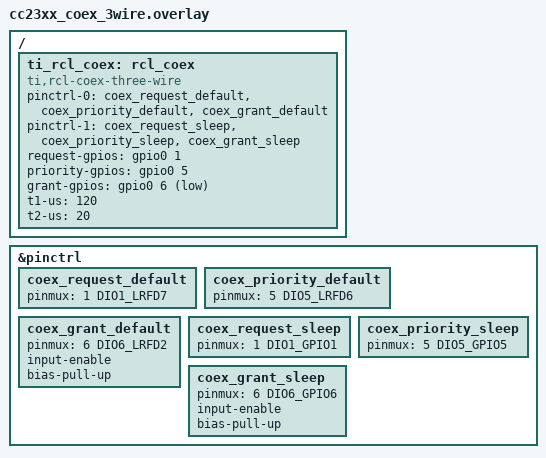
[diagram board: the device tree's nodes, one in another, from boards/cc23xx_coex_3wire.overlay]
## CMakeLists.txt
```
# SPDX-License-Identifier: Apache-2.0

cmake_minimum_required(VERSION 3.28.0)
find_package(Zephyr REQUIRED HINTS $ENV{ZEPHYR_BASE})
project(peripheral)

target_sources(app PRIVATE
  src/main.c
)
```

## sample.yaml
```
sample:
  name: Bluetooth Peripheral
  description: Demonstrates the Bluetooth LE Peripheral role
tests:
  sample.bluetooth.peripheral:
    harness: bluetooth
    platform_allow:
      - qemu_x86
      - lp_em_cc2340r5
      - lp_em_cc2340r5moda
      - lp_em_cc2340r53
      - lp_em_cc2340r53_wcsp
      - lp_em_cc2745r10_q1/cc2745r10_q1
      - lp_em_cc2745r10_q1/cc2755r10
      - lp_em_cc2755p10
      - lp_em_cc2755p20
      - nucleo_wb55rg
      - lp_em_cc35x1/cc3551e
    integration_platforms:
      - qemu_x86
    tags: bluetooth
  sample.bluetooth.peripheral.ti_lpf3.coex_3wire_cc23xx:
    harness: bluetooth
    platform_allow:
      - lp_em_cc2340r5
      - lp_em_cc2340r5moda
      - lp_em_cc2340r53
      - lp_em_cc2340r53_wcsp
    extra_args: EXTRA_DTC_OVERLAY_FILE=boards/cc23xx_coex_3wire.overlay
    extra_configs:
      - CONFIG_RCL_COEX=y
    tags: bluetooth
  sample.bluetooth.peripheral.ti_lpf3.coex_3wire_cc27xx:
    harness: bluetooth
    platform_allow:
      - lp_em_cc2745r10_q1/cc2745r10_q1
      - lp_em_cc2745r10_q1/cc2755r10
      - lp_em_cc2755p10
      - lp_em_cc2755p20
    extra_args: EXTRA_DTC_OVERLAY_FILE=boards/cc27xx_coex_3wire.overlay
    extra_configs:
      - CONFIG_RCL_COEX=y
    tags: bluetooth
  sample.bluetooth.peripheral.x_nucleo_idb05a1_shield:
    harness: bluetooth
    platform_allow: nucleo_l4r5zi
    depends_on:
      - arduino_spi
      - arduino_gpio
    extra_args: SHIELD=x_nucleo_idb05a1
    integration_platforms:
      - nucleo_l4r5zi
  sample.bluetooth.peripheral.no_blobs:
    extra_args:
      - CONFIG_BUILD_ONLY_NO_BLOBS=y
    platform_allow:
      - esp32_devkitc/esp32/procpu
      - esp32s3_devkitc/esp32s3/procpu
      - esp8684_devkitm
      - esp32c3_devkitc
      - esp32c6_devkitc/esp32c6/hpcore
      - esp32h2_devkitm
      - sltb010a/efr32bg22c224f512im40
      - xg24_rb4187c/efr32mg24b220f1536im48
      - xg27_dk2602a/efr32bg27c140f768im40
      - xg29_rb4412a/efr32mg29b140f1024im40
      - frdm_mcxw71
      - frdm_mcxw72
      - frdm_rw612
    build_only: true
```

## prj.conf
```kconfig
# Increased stack due to settings API usage
CONFIG_SYSTEM_WORKQUEUE_STACK_SIZE=2048

CONFIG_BT=y
CONFIG_LOG=y
CONFIG_BT_SMP=y
CONFIG_BT_PERIPHERAL=y
CONFIG_BT_DIS=y
CONFIG_BT_ATT_PREPARE_COUNT=5
CONFIG_BT_BAS=y
CONFIG_BT_HRS=y
CONFIG_BT_IAS=y
CONFIG_BT_CTS=y
CONFIG_BT_CTS_HELPER_API=y
CONFIG_BT_PRIVACY=y
CONFIG_BT_DEVICE_NAME="Zephyr Peripheral Sample Long Name"
CONFIG_BT_DEVICE_APPEARANCE=833
CONFIG_BT_DEVICE_NAME_DYNAMIC=y
CONFIG_BT_DEVICE_NAME_MAX=65

CONFIG_BT_KEYS_OVERWRITE_OLDEST=y
CONFIG_BT_SETTINGS=y
CONFIG_FLASH=y
CONFIG_FLASH_MAP=y
CONFIG_NVS=y
CONFIG_SETTINGS=y
```

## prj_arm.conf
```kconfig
CONFIG_BLUETOOTH=y
CONFIG_BLUETOOTH_LE=y
CONFIG_BLUETOOTH_DEBUG=y
CONFIG_BLUETOOTH_SMP=y
CONFIG_BLUETOOTH_SIGNING=y
CONFIG_TINYCRYPT=y
CONFIG_TINYCRYPT_AES=y
CONFIG_TEST_RANDOM_GENERATOR=y
CONFIG_BLUETOOTH_PERIPHERAL=y
```

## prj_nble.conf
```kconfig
CONFIG_BLUETOOTH=y
CONFIG_BLUETOOTH_CUSTOM=y
CONFIG_NBLE=y
CONFIG_BLUETOOTH_DEBUG_LOG=y
CONFIG_BLUETOOTH_ATT_PREPARE_COUNT=2
CONFIG_BLUETOOTH_DEVICE_NAME="Test peripheral"
```

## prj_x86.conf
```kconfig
CONFIG_TEST_RANDOM_GENERATOR=y
CONFIG_BLUETOOTH=y
CONFIG_BLUETOOTH_LE=y
CONFIG_BLUETOOTH_DEBUG=y
CONFIG_BLUETOOTH_SMP=y
CONFIG_BLUETOOTH_SIGNING=y
CONFIG_TINYCRYPT=y
CONFIG_TINYCRYPT_AES=y
CONFIG_BLUETOOTH_PERIPHERAL=y
CONFIG_BLUETOOTH_GATT_DYNAMIC_DB=y
```

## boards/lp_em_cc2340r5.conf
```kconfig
# Disable persistent storage to reduce RAM on cc2340r5
CONFIG_BT_KEYS_OVERWRITE_OLDEST=n
CONFIG_BT_SETTINGS=n
CONFIG_FLASH=n
CONFIG_FLASH_MAP=n
CONFIG_NVS=n
CONFIG_SETTINGS=n

# ATT prepare write not needed without persistent storage; 2 bufs sufficient for basic writes
CONFIG_BT_ATT_PREPARE_COUNT=2

# GATT cache is volatile without BT_SETTINGS (lost on reset), so caching provides no benefit
CONFIG_BT_GATT_CACHING=n
```

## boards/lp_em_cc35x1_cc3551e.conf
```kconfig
CONFIG_BT_HCI_TI_CC35XX=y

CONFIG_WIFI_TI_CC35XX=y
CONFIG_NET_L2_ETHERNET=y
CONFIG_NETWORKING=y
CONFIG_WIFI=y

# The CC35xx HSM/PSA integration is not ready for the Zephyr Bluetooth host.
CONFIG_ENTROPY_CC35XX_RNG=n
CONFIG_CRYPTO_TI_CC35XX=n
CONFIG_BT_GATT_CACHING=n
CONFIG_BT_SMP=n
CONFIG_BT_PRIVACY=n
CONFIG_BT_KEYS_OVERWRITE_OLDEST=n

CONFIG_BT_PHY_UPDATE=n
CONFIG_BT_AUTO_PHY_UPDATE=n

# Below memory constraints are enforced by the Wi-Fi stack
CONFIG_HEAP_MEM_POOL_SIZE=81920
CONFIG_MAIN_STACK_SIZE=61440
CONFIG_NET_TX_STACK_SIZE=2048
CONFIG_NET_RX_STACK_SIZE=2048
CONFIG_DYNAMIC_THREAD_PREFER_POOL=y
CONFIG_DYNAMIC_THREAD_POOL_SIZE=3
CONFIG_DYNAMIC_THREAD_STACK_SIZE=8192
CONFIG_NET_PKT_RX_COUNT=10
CONFIG_NET_PKT_TX_COUNT=10
CONFIG_NET_BUF_RX_COUNT=20
CONFIG_NET_BUF_TX_COUNT=20
CONFIG_NET_MAX_CONTEXTS=10
```

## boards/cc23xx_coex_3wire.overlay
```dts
/*
 * Copyright (c) 2026 Texas Instruments Incorporated
 *
 * SPDX-License-Identifier: Apache-2.0
 */

#include <zephyr/dt-bindings/pinctrl/cc23x0-pinctrl.h>
#include <zephyr/dt-bindings/gpio/gpio.h>

&pinctrl {
	coex_request_default: coex_request_default {
		pinmux = <1 DIO1_LRFD7>;	/* REQUEST - output using LRFD7 */
	};

	coex_priority_default: coex_priority_default {
		pinmux = <5 DIO5_LRFD6>;	/* PRIORITY - output using LRFD6 */
	};

	coex_grant_default: coex_grant_default {
		pinmux = <6 DIO6_LRFD2>;	/* GRANT - input using LRFD2 */
		input-enable;
		bias-pull-up;
	};

	coex_request_sleep: coex_request_sleep {
		pinmux = <1 DIO1_GPIO1>;
	};

	coex_priority_sleep: coex_priority_sleep {
		pinmux = <5 DIO5_GPIO5>;
	};

	coex_grant_sleep: coex_grant_sleep {
		pinmux = <6 DIO6_GPIO6>;
		input-enable;
		bias-pull-up;
	};
};

/ {
	ti_rcl_coex: rcl_coex {
		compatible = "ti,rcl-coex-three-wire";
		status = "okay";

		pinctrl-0 = <&coex_request_default &coex_priority_default &coex_grant_default>;
		pinctrl-1 = <&coex_request_sleep &coex_priority_sleep &coex_grant_sleep>;
		pinctrl-names = "default", "sleep";

		request-gpios = <&gpio0 1 GPIO_ACTIVE_HIGH>;
		priority-gpios = <&gpio0 5 GPIO_ACTIVE_HIGH>;
		grant-gpios = <&gpio0 6 GPIO_ACTIVE_LOW>;

		t1-us = <120>;  /* Time between REQUEST and RF activity (90-150 µs) */
		t2-us = <20>;   /* Priority indication time (15-20 µs) */
	};
};
```

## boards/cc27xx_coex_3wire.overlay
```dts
/*
 * Copyright (c) 2026 Texas Instruments Incorporated
 *
 * SPDX-License-Identifier: Apache-2.0
 */

#include <zephyr/dt-bindings/pinctrl/cc27xx-pinctrl.h>
#include <zephyr/dt-bindings/gpio/gpio.h>

&pinctrl {
	coex_request_default: coex_request_default {
		pinmux = <22 DIO22_LRFD5>;	/* REQUEST - output using LRFD5 */
	};

	coex_priority_default: coex_priority_default {
		pinmux = <27 DIO27_LRFD6>;	/* PRIORITY - output using LRFD6 */
	};

	coex_grant_default: coex_grant_default {
		pinmux = <21 DIO21_LRFD4>;	/* GRANT - input using LRFD4 */
		input-enable;
		bias-pull-up;
	};

	coex_request_sleep: coex_request_sleep {
		pinmux = <22 DIO22_GPIO22>;
	};

	coex_priority_sleep: coex_priority_sleep {
		pinmux = <27 DIO27_GPIO27>;
	};

	coex_grant_sleep: coex_grant_sleep {
		pinmux = <21 DIO21_GPIO21>;
		input-enable;
		bias-pull-up;
	};
};

/ {
	ti_rcl_coex: rcl_coex {
		compatible = "ti,rcl-coex-three-wire";
		status = "okay";

		pinctrl-0 = <&coex_request_default &coex_priority_default &coex_grant_default>;
		pinctrl-1 = <&coex_request_sleep &coex_priority_sleep &coex_grant_sleep>;
		pinctrl-names = "default", "sleep";

		request-gpios = <&gpio0 22 GPIO_ACTIVE_HIGH>;
		priority-gpios = <&gpio0 27 GPIO_ACTIVE_HIGH>;
		grant-gpios = <&gpio0 21 GPIO_ACTIVE_LOW>;

		t1-us = <120>;  /* Time between REQUEST and RF activity (90-150 µs) */
		t2-us = <20>;   /* Priority indication time (15-20 µs) */
	};
};
```

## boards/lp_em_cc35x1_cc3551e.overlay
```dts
/*
 * Copyright (c) 2025-2026 Conclusive Engineering Sp. z o.o.
 *
 * SPDX-License-Identifier: Apache-2.0
 */

&wlan0 {
	status = "okay";
};

&hci0 {
	status = "okay";
};
```

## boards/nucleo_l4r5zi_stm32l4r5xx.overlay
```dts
/*
 * SPDX-FileCopyrightText: Copyright The Zephyr Project Contributors
 * SPDX-License-Identifier: Apache-2.0
 */

&rng {
	status = "okay";
};
```

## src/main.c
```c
/* main.c - Application main entry point */

/*
 * Copyright (c) 2015-2016 Intel Corporation
 *
 * SPDX-License-Identifier: Apache-2.0
 */

#include <zephyr/types.h>
#include <stddef.h>
#include <string.h>
#include <errno.h>
#include <zephyr/sys/printk.h>
#include <zephyr/sys/byteorder.h>
#include <zephyr/kernel.h>

#include <zephyr/settings/settings.h>

#include <zephyr/bluetooth/bluetooth.h>
#include <zephyr/bluetooth/hci.h>
#include <zephyr/bluetooth/conn.h>
#include <zephyr/bluetooth/uuid.h>
#include <zephyr/bluetooth/gatt.h>
#include <zephyr/bluetooth/services/bas.h>
#include <zephyr/bluetooth/services/cts.h>
#include <zephyr/bluetooth/services/hrs.h>
#include <zephyr/bluetooth/services/ias.h>

/* Custom Service Variables */
#define BT_UUID_CUSTOM_SERVICE_VAL \
	BT_UUID_128_ENCODE(0x12345678, 0x1234, 0x5678, 0x1234, 0x56789abcdef0)

static const struct bt_uuid_128 vnd_uuid = BT_UUID_INIT_128(
	BT_UUID_CUSTOM_SERVICE_VAL);

static const struct bt_uuid_128 vnd_enc_uuid = BT_UUID_INIT_128(
	BT_UUID_128_ENCODE(0x12345678, 0x1234, 0x5678, 0x1234, 0x56789abcdef1));

static const struct bt_uuid_128 vnd_auth_uuid = BT_UUID_INIT_128(
	BT_UUID_128_ENCODE(0x12345678, 0x1234, 0x5678, 0x1234, 0x56789abcdef2));

#define VND_MAX_LEN 20
#define BT_HR_HEARTRATE_DEFAULT_MIN 90U
#define BT_HR_HEARTRATE_DEFAULT_MAX 160U

static uint8_t vnd_value[VND_MAX_LEN + 1] = { 'V', 'e', 'n', 'd', 'o', 'r'};
static uint8_t vnd_auth_value[VND_MAX_LEN + 1] = { 'V', 'e', 'n', 'd', 'o', 'r'};
static uint8_t vnd_wwr_value[VND_MAX_LEN + 1] = { 'V', 'e', 'n', 'd', 'o', 'r' };

static ssize_t read_vnd(struct bt_conn *conn, const struct bt_gatt_attr *attr,
			void *buf, uint16_t len, uint16_t offset)
{
	const char *value = attr->user_data;

	return bt_gatt_attr_read(conn, attr, buf, len, offset, value,
				 strlen(value));
}

static ssize_t write_vnd(struct bt_conn *conn, const struct bt_gatt_attr *attr,
			 const void *buf, uint16_t len, uint16_t offset,
			 uint8_t flags)
{
	uint8_t *value = attr->user_data;

	if (offset + len > VND_MAX_LEN) {
		return BT_GATT_ERR(BT_ATT_ERR_INVALID_OFFSET);
	}

	memcpy(value + offset, buf, len);
	value[offset + len] = 0;

	return len;
}

static uint8_t simulate_vnd;
static uint8_t indicating;
static struct bt_gatt_indicate_params ind_params;

static void vnd_ccc_cfg_changed(const struct bt_gatt_attr *attr, uint16_t value)
{
	simulate_vnd = (value == BT_GATT_CCC_INDICATE) ? 1 : 0;
}

static void indicate_cb(struct bt_conn *conn,
			struct bt_gatt_indicate_params *params, uint8_t err)
{
	printk("Indication %s\n", err != 0U ? "fail" : "success");
}

static void indicate_destroy(struct bt_gatt_indicate_params *params)
{
	printk("Indication complete\n");
	indicating = 0U;
}

#define VND_LONG_MAX_LEN 74
static uint8_t vnd_long_value[VND_LONG_MAX_LEN + 1] = {
		  'V', 'e', 'n', 'd', 'o', 'r', ' ', 'd', 'a', 't', 'a', '1',
		  'V', 'e', 'n', 'd', 'o', 'r', ' ', 'd', 'a', 't', 'a', '2',
		  'V', 'e', 'n', 'd', 'o', 'r', ' ', 'd', 'a', 't', 'a', '3',
		  'V', 'e', 'n', 'd', 'o', 'r', ' ', 'd', 'a', 't', 'a', '4',
		  'V', 'e', 'n', 'd', 'o', 'r', ' ', 'd', 'a', 't', 'a', '5',
		  'V', 'e', 'n', 'd', 'o', 'r', ' ', 'd', 'a', 't', 'a', '6',
		  '.', ' ' };

static ssize_t write_long_vnd(struct bt_conn *conn,
			      const struct bt_gatt_attr *attr, const void *buf,
			      uint16_t len, uint16_t offset, uint8_t flags)
{
	uint8_t *value = attr->user_data;

	if (flags & BT_GATT_WRITE_FLAG_PREPARE) {
		return 0;
	}

	if (offset + len > VND_LONG_MAX_LEN) {
		return BT_GATT_ERR(BT_ATT_ERR_INVALID_OFFSET);
	}

	memcpy(value + offset, buf, len);
	value[offset + len] = 0;

	return len;
}

static const struct bt_uuid_128 vnd_long_uuid = BT_UUID_INIT_128(
	BT_UUID_128_ENCODE(0x12345678, 0x1234, 0x5678, 0x1234, 0x56789abcdef3));

static struct bt_gatt_cep vnd_long_cep = {
	.properties = BT_GATT_CEP_RELIABLE_WRITE,
};

static const struct bt_uuid_128 vnd_write_cmd_uuid = BT_UUID_INIT_128(
	BT_UUID_128_ENCODE(0x12345678, 0x1234, 0x5678, 0x1234, 0x56789abcdef4));

static ssize_t write_without_rsp_vnd(struct bt_conn *conn,
				     const struct bt_gatt_attr *attr,
				     const void *buf, uint16_t len, uint16_t offset,
				     uint8_t flags)
{
	uint8_t *value = attr->user_data;

	if (!(flags & BT_GATT_WRITE_FLAG_CMD)) {
		/* Write Request received. Reject it since this Characteristic
		 * only accepts Write Without Response.
		 */
		return BT_GATT_ERR(BT_ATT_ERR_WRITE_REQ_REJECTED);
	}

	if (offset + len > VND_MAX_LEN) {
		return BT_GATT_ERR(BT_ATT_ERR_INVALID_OFFSET);
	}

	memcpy(value + offset, buf, len);
	value[offset + len] = 0;

	return len;
}

/* Vendor Primary Service Declaration */
BT_GATT_SERVICE_DEFINE(vnd_svc,
	BT_GATT_PRIMARY_SERVICE(&vnd_uuid),
	BT_GATT_CHARACTERISTIC(&vnd_enc_uuid.uuid,
			       BT_GATT_CHRC_READ | BT_GATT_CHRC_WRITE |
			       BT_GATT_CHRC_INDICATE,
			       BT_GATT_PERM_READ_ENCRYPT |
			       BT_GATT_PERM_WRITE_ENCRYPT,
			       read_vnd, write_vnd, vnd_value),
	BT_GATT_CCC(vnd_ccc_cfg_changed,
		    BT_GATT_PERM_READ | BT_GATT_PERM_WRITE_ENCRYPT),
	BT_GATT_CHARACTERISTIC(&vnd_auth_uuid.uuid,
			       BT_GATT_CHRC_READ | BT_GATT_CHRC_WRITE,
			       BT_GATT_PERM_READ_AUTHEN |
			       BT_GATT_PERM_WRITE_AUTHEN,
			       read_vnd, write_vnd, vnd_auth_value),
	BT_GATT_CHARACTERISTIC(&vnd_long_uuid.uuid, BT_GATT_CHRC_READ |
			       BT_GATT_CHRC_WRITE | BT_GATT_CHRC_EXT_PROP,
			       BT_GATT_PERM_READ | BT_GATT_PERM_WRITE |
			       BT_GATT_PERM_PREPARE_WRITE,
			       read_vnd, write_long_vnd, &vnd_long_value),
	BT_GATT_CEP(&vnd_long_cep),
	BT_GATT_CHARACTERISTIC(&vnd_write_cmd_uuid.uuid,
			       BT_GATT_CHRC_WRITE_WITHOUT_RESP,
			       BT_GATT_PERM_WRITE, NULL,
			       write_without_rsp_vnd, &vnd_wwr_value),
);

static const struct bt_data ad[] = {
	BT_DATA_BYTES(BT_DATA_FLAGS, (BT_LE_AD_GENERAL | BT_LE_AD_NO_BREDR)),
	BT_DATA_BYTES(BT_DATA_UUID16_ALL,
		      BT_UUID_16_ENCODE(BT_UUID_HRS_VAL),
		      BT_UUID_16_ENCODE(BT_UUID_BAS_VAL),
		      BT_UUID_16_ENCODE(BT_UUID_CTS_VAL)),
	BT_DATA_BYTES(BT_DATA_UUID128_ALL, BT_UUID_CUSTOM_SERVICE_VAL),
};

static const struct bt_data sd[] = {
	BT_DATA(BT_DATA_NAME_COMPLETE, CONFIG_BT_DEVICE_NAME, sizeof(CONFIG_BT_DEVICE_NAME) - 1),
};

void mtu_updated(struct bt_conn *conn, uint16_t tx, uint16_t rx)
{
	printk("Updated MTU: TX: %d RX: %d bytes\n", tx, rx);
}

static struct bt_gatt_cb gatt_callbacks = {
	.att_mtu_updated = mtu_updated
};

static void connected(struct bt_conn *conn, uint8_t err)
{
	if (err) {
		printk("Connection failed, err 0x%02x %s\n", err, bt_hci_err_to_str(err));
	} else {
		printk("Connected\n");
	}
}

static void disconnected(struct bt_conn *conn, uint8_t reason)
{
	printk("Disconnected, reason 0x%02x %s\n", reason, bt_hci_err_to_str(reason));
}

static void alert_stop(void)
{
	printk("Alert stopped\n");
}

static void alert_start(void)
{
	printk("Mild alert started\n");
}

static void alert_high_start(void)
{
	printk("High alert started\n");
}

BT_CONN_CB_DEFINE(conn_callbacks) = {
	.connected = connected,
	.disconnected = disconnected,
};

BT_IAS_CB_DEFINE(ias_callbacks) = {
	.no_alert = alert_stop,
	.mild_alert = alert_start,
	.high_alert = alert_high_start,
};

static void bt_ready(void)
{
	int err;

	printk("Bluetooth initialized\n");

	if (IS_ENABLED(CONFIG_SETTINGS)) {
		settings_load();
	}

	err = bt_le_adv_start(BT_LE_ADV_CONN_FAST_1, ad, ARRAY_SIZE(ad), sd, ARRAY_SIZE(sd));
	if (err) {
		printk("Advertising failed to start (err %d)\n", err);
		return;
	}

	printk("Advertising successfully started\n");
}

#if defined(CONFIG_BT_SMP)
static void auth_passkey_display(struct bt_conn *conn, unsigned int passkey)
{
	char addr[BT_ADDR_LE_STR_LEN];

	bt_addr_le_to_str(bt_conn_get_dst(conn), addr, sizeof(addr));

	printk("Passkey for %s: %06u\n", addr, passkey);
}

static void auth_cancel(struct bt_conn *conn)
{
	char addr[BT_ADDR_LE_STR_LEN];

	bt_addr_le_to_str(bt_conn_get_dst(conn), addr, sizeof(addr));

	printk("Pairing cancelled: %s\n", addr);
}

static struct bt_conn_auth_cb auth_cb_display = {
	.passkey_display = auth_passkey_display,
	.passkey_entry = NULL,
	.cancel = auth_cancel,
};
#endif

static void bas_notify(void)
{
	uint8_t battery_level = bt_bas_get_battery_level();

	battery_level--;

	if (!battery_level) {
		battery_level = 100U;
	}

	bt_bas_set_battery_level(battery_level);
}

static uint8_t bt_heartrate = BT_HR_HEARTRATE_DEFAULT_MIN;

static void hrs_notify(void)
{
	/* Heartrate measurements simulation */
	bt_heartrate++;
	if (bt_heartrate == BT_HR_HEARTRATE_DEFAULT_MAX) {
		bt_heartrate = BT_HR_HEARTRATE_DEFAULT_MIN;
	}

	bt_hrs_notify(bt_heartrate);
}

/**
 * variable to hold reference milliseconds to epoch when device booted
 * this is only for demo purpose, for more precise synchronization please
 * review clock_settime API implementation.
 */
static struct bt_cts_local_time local_time = {
	.timezone_offset = BT_CTS_TIMEZONE_DEFAULT_VALUE,
	.dst_offset = BT_CTS_DST_OFFSET_UNKNOWN,
};
static bool cts_notification_enabled;
static int64_t unix_ms_ref;

static void cts_notification_changed_cb(bool enabled)
{
	cts_notification_enabled = enabled;
}

static int cts_time_write_cb(struct bt_cts_time_format *cts_time)
{
	int err;
	int64_t unix_ms;

	if (IS_ENABLED(CONFIG_BT_CTS_HELPER_API)) {
		err = bt_cts_time_to_unix_ms(cts_time, &unix_ms);
		if (err != 0) {
			return err;
		}
	} else {
		return -ENOTSUP;
	}

	/* recalculate reference value */
	unix_ms_ref = unix_ms - k_uptime_get();
	return 0;
}

static int cts_fill_current_cts_time_cb(struct bt_cts_time_format *cts_time)
{
	int64_t unix_ms = unix_ms_ref + k_uptime_get();

	if (IS_ENABLED(CONFIG_BT_CTS_HELPER_API)) {
		return bt_cts_time_from_unix_ms(cts_time, unix_ms);
	} else {
		return -ENOTSUP;
	}
}

static int cts_local_time_write_cb(const struct bt_cts_local_time *cts_local_time)
{
	memcpy(&local_time, cts_local_time, sizeof(local_time));
	return 0;
}

static int cts_fill_local_time_cb(struct bt_cts_local_time *cts_local_time)
{
	memcpy(cts_local_time, &local_time, sizeof(local_time));
	return 0;
}

const struct bt_cts_cb cts_cb = {
	.notification_changed = cts_notification_changed_cb,
	.cts_time_write = cts_time_write_cb,
	.fill_current_cts_time = cts_fill_current_cts_time_cb,
	.cts_local_time_write = cts_local_time_write_cb,
	.fill_current_cts_local_time = cts_fill_local_time_cb,
};

static int bt_hrs_ctrl_point_write(uint8_t request)
{
	printk("HRS Control point request: %d\n", request);
	if (request != BT_HRS_CONTROL_POINT_RESET_ENERGY_EXPANDED_REQ) {
		return -ENOTSUP;
	}

	bt_heartrate = BT_HR_HEARTRATE_DEFAULT_MIN;
	return 0;
}

static struct bt_hrs_cb hrs_cb = {
	.ctrl_point_write = bt_hrs_ctrl_point_write,
};

int main(void)
{
	struct bt_gatt_attr *vnd_ind_attr;
	char str[BT_UUID_STR_LEN];
	int err;

	err = bt_enable(NULL);
	if (err != 0) {
		printk("Bluetooth init failed (err %d)\n", err);
		return 0;
	}

	bt_ready();
	bt_cts_init(&cts_cb);
	bt_hrs_cb_register(&hrs_cb);

	bt_gatt_cb_register(&gatt_callbacks);
#if defined(CONFIG_BT_SMP)
	bt_conn_auth_cb_register(&auth_cb_display);
#endif

	vnd_ind_attr = bt_gatt_find_by_uuid(vnd_svc.attrs, vnd_svc.attr_count,
					    &vnd_enc_uuid.uuid);
	bt_uuid_to_str(&vnd_enc_uuid.uuid, str, sizeof(str));
	printk("Indicate VND attr %p (UUID %s)\n", vnd_ind_attr, str);

	/* Implement notification. At the moment there is no suitable way
	 * of starting delayed work so we do it here
	 */
	while (1) {
		k_sleep(K_SECONDS(1));

		/* Current time update notification example
		 * For testing purposes, we send a manual update notification every second.
		 * In production `bt_cts_send_notification` should only be used when time is changed
		 */
		if (cts_notification_enabled) {
			bt_cts_send_notification(BT_CTS_UPDATE_REASON_MANUAL);
		}
		/* Heartrate measurements simulation */
		hrs_notify();

		/* Battery level simulation */
		bas_notify();

		/* Vendor indication simulation */
		if (simulate_vnd && vnd_ind_attr) {
			if (indicating) {
				continue;
			}

			ind_params.attr = vnd_ind_attr;
			ind_params.func = indicate_cb;
			ind_params.destroy = indicate_destroy;
			ind_params.data = &indicating;
			ind_params.len = sizeof(indicating);

			if (bt_gatt_indicate(NULL, &ind_params) == 0) {
				indicating = 1U;
			}
		}
	}
	return 0;
}
```

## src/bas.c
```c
/* Workaround build system bug that will put objects in source dir */
#include "../../gatt/bas.c"
```

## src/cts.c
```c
/** @file
 *  @brief CTS Service sample
 */

/*
 * Copyright (c) 2016 Intel Corporation
 *
 * SPDX-License-Identifier: Apache-2.0
 */

#include <zephyr/types.h>
#include <stddef.h>
#include <string.h>
#include <errno.h>
#include <zephyr/sys/printk.h>
#include <zephyr/sys/byteorder.h>
#include <zephyr/kernel.h>

#include <zephyr/bluetooth/bluetooth.h>
#include <zephyr/bluetooth/hci.h>
#include <zephyr/bluetooth/conn.h>
#include <zephyr/bluetooth/uuid.h>
#include <zephyr/bluetooth/gatt.h>

static uint8_t ct[10];
static uint8_t ct_update;

static void ct_ccc_cfg_changed(const struct bt_gatt_attr *attr, uint16_t value)
{
	/* TODO: Handle value */
}

static k_ssize_t read_ct(struct bt_conn *conn, const struct bt_gatt_attr *attr,
		       void *buf, uint16_t len, uint16_t offset)
{
	const char *value = attr->user_data;

	return bt_gatt_attr_read(conn, attr, buf, len, offset, value,
				 sizeof(ct));
}

static k_ssize_t write_ct(struct bt_conn *conn, const struct bt_gatt_attr *attr,
			const void *buf, uint16_t len, uint16_t offset,
			uint8_t flags)
{
	uint8_t *value = attr->user_data;

	if (offset + len > sizeof(ct)) {
		return BT_GATT_ERR(BT_ATT_ERR_INVALID_OFFSET);
	}

	memcpy(value + offset, buf, len);
	ct_update = 1U;

	return len;
}

/* Current Time Service Declaration */
BT_GATT_SERVICE_DEFINE(cts_cvs,
	BT_GATT_PRIMARY_SERVICE(BT_UUID_CTS),
	BT_GATT_CHARACTERISTIC(BT_UUID_CTS_CURRENT_TIME, BT_GATT_CHRC_READ |
			       BT_GATT_CHRC_NOTIFY | BT_GATT_CHRC_WRITE,
			       BT_GATT_PERM_READ | BT_GATT_PERM_WRITE,
			       read_ct, write_ct, ct),
	BT_GATT_CCC(ct_ccc_cfg_changed, BT_GATT_PERM_READ | BT_GATT_PERM_WRITE),
);

static void generate_current_time(uint8_t *buf)
{
	uint16_t year;

	/* 'Exact Time 256' contains 'Day Date Time' which contains
	 * 'Date Time' - characteristic contains fields for:
	 * year, month, day, hours, minutes and seconds.
	 */

	year = sys_cpu_to_le16(2015);
	memcpy(buf,  &year, 2); /* year */
	buf[2] = 5U; /* months starting from 1 */
	buf[3] = 30U; /* day */
	buf[4] = 12U; /* hours */
	buf[5] = 45U; /* minutes */
	buf[6] = 30U; /* seconds */

	/* 'Day of Week' part of 'Day Date Time' */
	buf[7] = 1U; /* day of week starting from 1 */

	/* 'Fractions 256 part of 'Exact Time 256' */
	buf[8] = 0U;

	/* Adjust reason */
	buf[9] = 0U; /* No update, change, etc */
}

void cts_init(void)
{
	/* Simulate current time for Current Time Service */
	generate_current_time(ct);
}

void cts_notify(void)
{	/* Current Time Service updates only when time is changed */
	if (!ct_update) {
		return;
	}

	ct_update = 0U;
	bt_gatt_notify(NULL, &cts_cvs.attrs[1], &ct, sizeof(ct));
}
```

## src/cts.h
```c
/** @file
 *  @brief CTS Service sample
 */

/*
 * Copyright (c) 2016 Intel Corporation
 *
 * SPDX-License-Identifier: Apache-2.0
 */

#ifdef __cplusplus
extern "C" {
#endif

void cts_init(void);
void cts_notify(void);

#ifdef __cplusplus
}
#endif
```
